# SIM3L168_A register map
File version: 1
CPU: 
Registers are 32-bit, read-write, reset 0x0 unless marked. A register's access mark holds for its fields unless they carry their own. Offsets are from the block's base; [hi:lo] are bit positions.

## LOCK_0
Base 0x40049000
0x00 KEY — Security Key
  [7:0] KEY — Peripheral Lock Mask Key.
    0=LOCKED (PERIPHLOCK registers are locked and no valid values have been written to KEY.); 1=INTERMEDIATE (PERIPHLOCK registers are locked and the first valid value (0xA5) has been written to KEY.); 2=UNLOCKED (PERIPHLOCK registers are unlocked. Any subsequent writes to KEY will lock the interface.)
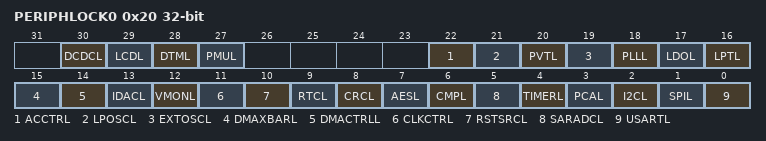
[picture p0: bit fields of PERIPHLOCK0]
0x20 PERIPHLOCK0 — Peripheral Lock Control 0
  [30] DCDCL — DC-DC Converter Module Lock.
    0=UNLOCKED (Unlock the DCDC0 Module registers.); 1=LOCKED (Lock the DCDC0 Module registers (bits can still be read).)
  [29] LCDL — LCD Module Lock.
    0=UNLOCKED (Unlock the LCD0 Module registers.); 1=LOCKED (Lock the LCD0 Module registers (bits can still be read).)
  [28] DTML — DTM Module Lock.
    0=UNLOCKED (Unlock the DTM0, DTM1, and DTM2 Module registers.); 1=LOCKED (Lock the DTM0, DTM1, and DTM2 Module registers (bits can still be read).)
  [27] PMUL — PMU Module Lock Enable.
    0=UNLOCKED (Unlock the PMU Module registers.); 1=LOCKED (Lock the PMU Module registers (bits can still be read).)
  [22] ACCTRL — Advanced Capture Counter Module Lock.
    0=UNLOCKED (Unlock the Advanced Capture Counter (ACCTR0) Module registers.); 1=LOCKED (Lock the Advanced Capture Counter (ACCTR0) Module registers (bits can still be read).)
  [21] LPOSCL — Low Power Oscillator Lock Enable.
    0=UNLOCKED (Unlock the Low Power Oscillator (LPOSC0) Module registers.); 1=LOCKED (Lock the Low Power Oscillator (LPOSC0) Module registers (bits can still be read).)
  [20] PVTL — PVT Oscillator Module Lock Enable.
    0=UNLOCKED (Unlock the PVTOSC0 Module registers.); 1=LOCKED (Lock the PVTOSC0 Module registers (bits can still be read).)
  [19] EXTOSCL — External Oscillator Module Lock Enable.
    0=UNLOCKED (Unlock the External Oscillator (EXTOSC0) Module registers.); 1=LOCKED (Lock the External Oscillator (EXTOSC0) Module registers (bits can still be read).)
  [18] PLLL — PLL Module Lock Enable.
    0=UNLOCKED (Unlock the PLL0 Module registers.); 1=LOCKED (Lock the PLL0 Module registers (bits can still be read).)
  [17] LDOL — Voltage Reference Module Lock Enable.
    0=UNLOCKED (Unlock the LDO0 Module registers.); 1=LOCKED (Lock the LDO0 Module registers (bits can still be read).)
  [16] LPTL — Low Power Timer Module Lock Enable.
    0=UNLOCKED (Unlock the Low Power Timer (LPTIMER0) Module registers.); 1=LOCKED (Lock the Low Power Timer (LPTIMER0) Module registers (bits can still be read).)
  [15] DMAXBARL — DMA Crossbar Module Lock Enable.
    0=UNLOCKED (Unlock the DMA Crossbar (DMAXBAR0) Module registers.); 1=LOCKED (Lock the DMA Crossbar (DMAXBAR0) Module registers (bits can still be read).)
  [14] DMACTRLL — DMA Controller Module Lock Enable.
    0=UNLOCKED (Unlock the DMA Controller (DMACTRL0) Module registers.); 1=LOCKED (Lock the DMA Controller (DMACTRL0) Module registers (bits can still be read).)
  [13] IDACL — IDAC Module Lock Enable.
    0=UNLOCKED (Unlock the IDAC0 Module registers.); 1=LOCKED (Lock the IDAC0 Module registers (bits can still be read).)
  [12] VMONL — Voltage Supply Monitor Module Lock Enable.
    0=UNLOCKED (Unlock the Voltage Supply Monitor (VMON0) Module registers.); 1=LOCKED (Lock the Voltage Supply Monitor (VMON0) Module registers (bits can still be read).)
  [11] CLKCTRL — Clock Control Lock Enable.
    0=UNLOCKED (Unlock the Clock Control (CLKCTRL)Module registers.); 1=LOCKED (Lock the Clock Control (CLKCTRL) Module registers (bits can still be read).)
  [10] RSTSRCL — Reset Sources Module Lock Enable.
    0=UNLOCKED (Unlock the Reset Sources (RSTSRC) Module registers.); 1=LOCKED (Lock the Reset Sources (RSTSRC) Module registers (bits can still be read).)
  [9] RTCL — RTC Module Lock Enable.
    0=UNLOCKED (Unlock the RTC0 Module registers.); 1=LOCKED (Lock the RTC0 Module registers (bits can still be read).)
  [8] CRCL — CRC Module Lock Enable.
    0=UNLOCKED (Unlock the CRC0 Module registers.); 1=LOCKED (Lock the CRC0 Module registers (bits can still be read).)
  [7] AESL — AES Module Lock Enable.
    0=UNLOCKED (Unlock the AES0 Module registers.); 1=LOCKED (Lock the AES0 Module registers (bits can still be read).)
  [6] CMPL — Comparator Module Lock Enable.
    0=UNLOCKED (Unlock the Comparator 0 and Comparator 1 Module registers.); 1=LOCKED (Lock the Comparator 0 and Comparator 1 Module registers (bits can still be read).)
  [5] SARADCL — SARADC Module Lock Enable.
    0=UNLOCKED (Unlock the SARADC0 Module registers.); 1=LOCKED (Lock the SARADC0 Module registers (bits can still be read).)
  [4] TIMERL — Timer Module Lock Enable.
    0=UNLOCKED (Unlock the TIMER0, TIMER1, and TIMER2 Module registers.); 1=LOCKED (Lock the TIMER0, TIMER1, and TIMER2 Module registers (bits can still be read).)
  [3] PCAL — PCA Module Lock Enable.
    0=UNLOCKED (Unlock the EPCA0 Module registers.); 1=LOCKED (Lock the EPCA0 Module registers (bits can still be read).)
  [2] I2CL — I2C Module Lock Enable.
    0=UNLOCKED (Unlock the I2C0 Module registers.); 1=LOCKED (Lock the I2C0 Module registers (bits can still be read).)
  [1] SPIL — SPI Module Lock Enable.
    0=UNLOCKED (Unlock the SPI0 and SPI1 Module registers.); 1=LOCKED (Lock the SPI0 and SPI1 Module registers (bits can still be read).)
  [0] USARTL — USART/UART Module Lock Enable.
    0=UNLOCKED (Unlock the USART0 and UART0 Module registers.); 1=LOCKED (Lock the USART0 and UART0 Module registers (bits can still be read).)
0x40 PERIPHLOCK1 — Peripheral Lock Control 1
  [0] ENCDECL — Encoder Decoder Module Lock.
    0=UNLOCKED (Unlock the ENCDEC0 Module registers.); 1=LOCKED (Lock the ENCDEC0 Module registers (bits can still be read).)
